# STM32WBA54 register map
File version: 1.0
CPU: CM33 r0p1, little endian, MPU, FPU, 4 interrupt priority bits
Registers are 32-bit, read-write, reset 0x0 unless marked. A register's access mark holds for its fields unless they carry their own. Offsets are from the block's base; [hi:lo] are bit positions; {n}, {i} and the like mark numbered series.

## EXTI — External interrupt/event controller
Base 0x46022000
Same registers: SEC_EXTI 0x56022000
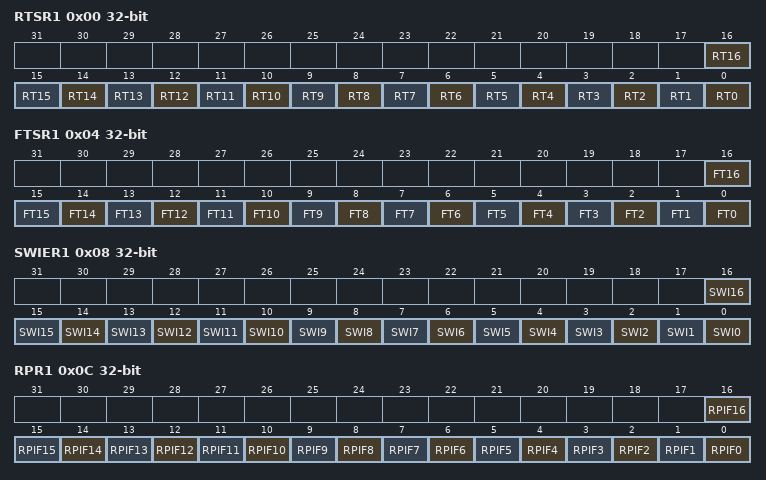
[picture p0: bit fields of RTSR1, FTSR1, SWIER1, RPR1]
0x00 RTSR1 — EXTI rising trigger selection register
  [n] RT{n} (n=0..16) — Rising trigger event configuration bit of configurable event input x When EXTI_SECCFGR.SECx is disabled, RTx can be accessed with non-secure and secure access. When EXTI_SECCFGR.SECx is enabled, RTx can only be accessed with secure access. Non-secure write to this bit x is discarded and non-secure read returns 0. When EXTI_PRIVCFGR.PRIVx is disabled, RTx can be accessed with unprivileged and privileged access. When EXTI_PRIVCFGR.PRIVx is enabled, RTx can only be accessed with privileged access. Unprivileged write to this bit x is discarded, unprivileged read returns 0.
0x04 FTSR1 — EXTI falling trigger selection register
  [n] FT{n} (n=0..16) — Falling trigger event configuration bit of configurable event input x When EXTI_SECCFGR.SECx is disabled, FTx can be accessed with non-secure and secure access. When EXTI_SECCFGR.SECx is enabled, FTx can only be accessed with secure access. Non-secure write to this FTx is discarded, non-secure read returns 0. When EXTI_PRIVCFGR.PRIVx is disabled, FTx can be accessed with unprivileged and privileged access. When EXTI_PRIVCFGR.PRIVx is enabled, FTx can only be accessed with privileged access. Unprivileged write to this FTx is discarded, unprivileged read returns 0.
0x08 SWIER1 — EXTI software interrupt event register
  [n] SWI{n} (n=0..16) — Software interrupt on event x When EXTI_SECFGR.SECx is disabled, SWIx can be accessed with non-secure and secure access. When EXTI_SECCFGR.SECx is enabled, SWIx can only be accessed with secure access. Non-secure write to this SWI x is discarded, non-secure read returns 0. When EXTI_PRIVCFGR.PRIVx is disabled, SWIx can be accessed with unprivileged and privileged access. When EXTI_PRIVCFGR.PRIVx is enabled, SWIx can only be accessed with privileged access. Unprivileged write to this SWIx is discarded, unprivileged read returns 0. A software interrupt is generated independently from the setting in EXTI_RTSR and EXTI_FTSR. It always returns 0 when read.
0x0C RPR1 — EXTI rising edge pending register
  [n] RPIF{n} (n=0..16) — configurable event inputs x rising edge pending bit When EXTI_SECCFGR.SECx is disabled, RPIFx can be accessed with non-secure and secure access. When EXTI_SECCFGR.SECx is enabled, RPIFx can only be accessed with secure access. Non-secure write to this RPIFx is discarded, non-secure read returns 0. When EXTI_PRIVCFGR.PRIVx is disabled, RPIFx can be accessed with unprivileged and privileged access. When EXTI_PRIVCFGR.PRIVx is enabled, RPIFx can only be accessed with privileged access. Unprivileged write to this RPIFx is discarded, unprivileged read returns 0. This bit is set when the rising edge event or an EXTI_SWIER software trigger arrives on the configurable event line. This bit is cleared by writing 1 to it.
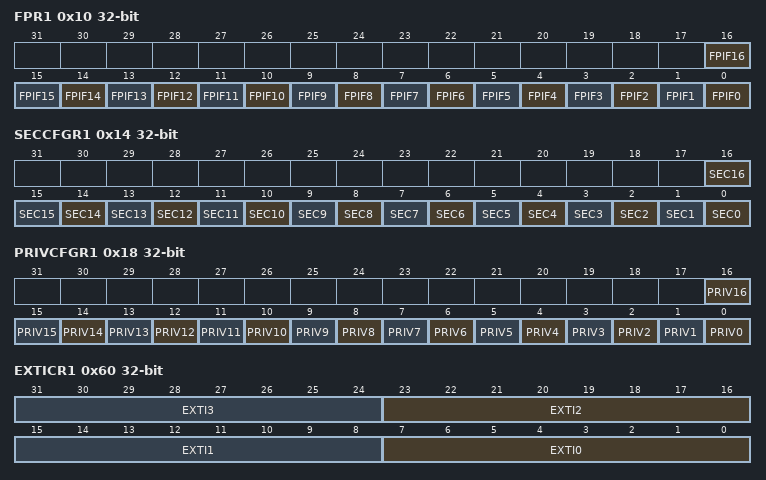
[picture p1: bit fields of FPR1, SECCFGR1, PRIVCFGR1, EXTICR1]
0x10 FPR1 — EXTI falling edge pending register
  [n] FPIF{n} (n=0..16) — configurable event inputs x falling edge pending bit When EXTI_SECCFGR.SECx is disabled, FPIFx can be accessed with non-secure and secure access. When EXTI_SECCFGR.SECx is enabled, FPIFx can only be accessed with secure access. Non-secure write to this FPIFx is discarded, non-secure read returns 0. When EXTI_PRIVCFGR.PRIVx is disabled, FPIFx can be accessed with unprivileged and privileged access. When EXTI_PRIVCFGR.PRIVx is enabled, FPIFx can only be accessed with privileged access. Unprivileged write to this FPIFx is discarded, unprivileged read returns 0. This bit is set when the falling edge event arrives on the configurable event line. This bit is cleared by writing 1 to it.
0x14 SECCFGR1 — EXTI security configuration register
  [n] SEC{n} (n=0..16) — Security enable on event input x When EXTI_PRIVCFGR.PRIVx is disabled, SECx can be accessed with privileged and unprivileged access. When EXTI_PRIVCFGR.PRIVx is enabled, SECx can only be written with privileged access. Unprivileged write to this SECx is discarded.
0x18 PRIVCFGR1 — EXTI privilege configuration register
  [n] PRIV{n} (n=0..16) — Security enable on event input x When EXTI_SECCFGR.SECx is disabled, PRIVx can be accessed with secure and non-secure access. When EXTI_SECCFGR.SECx is enabled, PRIVx can only be written with secure access. Non-secure write to this PRIVx is discarded.
0x60 EXTICR1 — EXTI external interrupt selection register
  [8n+7:8n] EXTI{n} (n=0..3) — EXTI{n} GPIO port selection These bits are written by software to select the source input for EXTI{n} external interrupt. When EXTI_SECCFGR.SEC{n} is disabled, EXTI{n} can be accessed with non-secure and secure access. When EXTI_SECCFGR.SEC{n} is enabled, EXTI{n} can only be accessed with secure access. Non-secure write is discarded and non-secure read returns 0. When EXTI_PRIVCFGR.PRIV{n} is disabled, EXTI{n} can be accessed with privileged and unprivileged access. When EXTI_PRIVCFGR.PRIV{n} is enabled, EXTI{n} can only be accessed with privileged access. Unprivileged write to this bit is discarded. Others: reserved
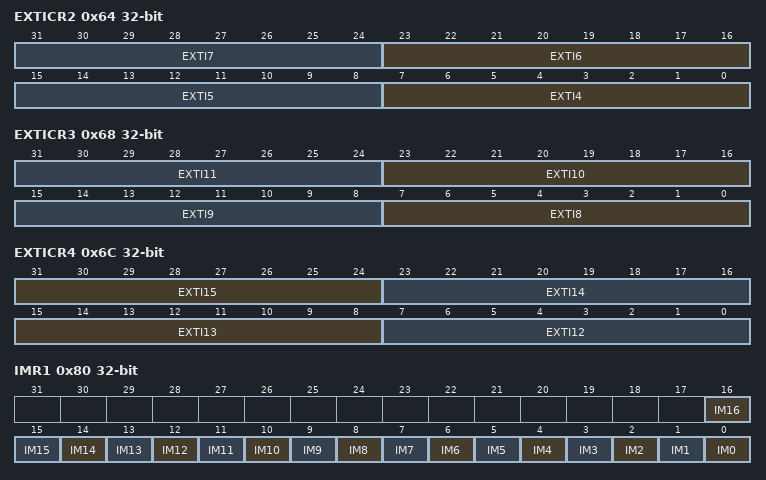
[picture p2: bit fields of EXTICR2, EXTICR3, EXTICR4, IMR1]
0x64 EXTICR2 — EXTI external interrupt selection register
  [8n-25:8n-32] EXTI{n} (n=4..7) — EXTI{n} GPIO port selection These bits are written by software to select the source input for EXTI{n} external interrupt. When EXTI_SECCFGR.SEC{n} is disabled, EXTI{n} can be accessed with non-secure and secure access. When EXTI_SECCFGR.SEC{n} is enabled, EXTI{n} can only be accessed with secure access. Non-secure write is discarded and non-secure read returns 0. When EXTI_PRIVCFGR.PRIV{n} is disabled, EXTI{n} can be accessed with privileged and unprivileged access. When EXTI_PRIVCFGR.PRIV{n} is enabled, EXTI{n} can only be accessed with privileged access. Unprivileged write to this bit is discarded. Others: reserved
0x68 EXTICR3 — EXTI external interrupt selection register
  [8n-57:8n-64] EXTI{n} (n=8..11) — EXTI{n} GPIO port selection These bits are written by software to select the source input for EXTI{n} external interrupt. When EXTI_SECCFGR.SEC{n} is disabled, EXTI{n} can be accessed with non-secure and secure access. When EXTI_SECCFGR.SEC{n} is enabled, EXTI{n} can only be accessed with secure access. Non-secure write is discarded and non-secure read returns 0. When EXTI_PRIVCFGR.PRIV{n} is disabled, EXTI{n} can be accessed with privileged and unprivileged access. When EXTI_PRIVCFGR.PRIV{n} is enabled, EXTI{n} can only be accessed with privileged access. Unprivileged write to this bit is discarded. Others: reserved
0x6C EXTICR4 — EXTI external interrupt selection register
  [31:24] EXTI15 — EXTI15 GPIO port selection These bits are written by software to select the source input for EXTI15 external interrupt. When EXTI_SECCFGR.SEC15 is disabled, EXTI15 can be accessed with non-secure and secure access. When EXTI_SECCFGR.SEC15 is enabled, EXTI15 can only be accessed with secure access. Non-secure write is discarded and non-secure read returns 0. When EXTI_PRIVCFGR.PRIV15 is disabled, EXTI15 can be accessed with privileged and unprivileged access. When EXTI_PRIVCFGR.PRIV15 is enabled, EXTI15 can only be accessed with privileged access. Unprivileged write to this bit is discarded. Others: reserved
  [23:16] EXTI14 — EXTI14 GPIO port selection These bits are written by software to select the source input for EXTI14 external interrupt. When EXTI_SECCFGR.SEC14 is disabled, EXTI14 can be accessed with non-secure and secure access. When EXTI_SECCFGR.SEC14 is enabled, EXTI14 can only be accessed with secure access. Non-secure write is discarded and non-secure read returns 0. When EXTI_PRIVCFGR.PRIV14 is disabled, EXTI14 can be accessed with privileged and unprivileged access. When EXTI_PRIVCFGR.PRIV14 is enabled, EXTI14 can only be accessed with privileged access. Unprivileged write to this bit is discarded. Others: reserved
  [15:8] EXTI13 — EXTI13 GPIO port selection These bits are written by software to select the source input for EXTI13 external interrupt. When EXTI_SECCFGR.SEC13 is disabled, EXTI13 can be accessed with non-secure and secure access. When EXTI_SECCFGR.SEC13 is enabled, EXTI13 can only be accessed with secure access. Non-secure write is discarded and non-secure read returns 0. When EXTI_PRIVCFGR.PRIV13 is disabled, EXTI13 can be accessed with privileged and unprivileged access. When EXTI_PRIVCFGR.PRIV13 is enabled, EXTI13 can only be accessed with privileged access. Unprivileged write to this bit is discarded. Others: reserved
  [7:0] EXTI12 — EXTI0 GPIO port selection These bits are written by software to select the source input for EXTI12 external interrupt. When EXTI_SECCFGR.SEC12 is disabled, EXTI12 can be accessed with non-secure and secure access. When EXTI_SECCFGR.SEC12 is enabled, EXTI12 can only be accessed with secure access. Non-secure write is discarded and non-secure read returns 0. When EXTI_PRIVCFGR.PRIV12 is disabled, EXTI12 can be accessed with privileged and unprivileged access. When EXTI_PRIVCFGR.PRIV12 is enabled, EXTI12 can only be accessed with privileged access. Unprivileged write to this bit is discarded. Others: reserved
0x70 LOCKR — EXTI lock register
  [0] LOCK — Global security and privilege configuration registers (EXTI_SECCFGR and EXTI_PRIVCFGR) lock This bit is written once after reset.
0x80 IMR1 — EXTI CPU wakeup with interrupt mask register
  [n] IM{n} (n=0..16) — CPU wakeup with interrupt mask on event input x When EXTI_SECCFGR.SECx is disabled, IMx can be accessed with non-secure and secure access. When EXTI_SECCFGR.SECx is enabled, IMx can only be accessed with secure access. Non-secure write to this bit is discarded and non-secure read returns 0. When EXTI_PRIVCFGR.PRIVx is disabled, IMx can be accessed with privileged and unprivileged access. When EXTI_PRIVCFGR.PRIVx is enabled, IMx can only be accessed with privileged access. Unprivileged write to this bit is discarded.
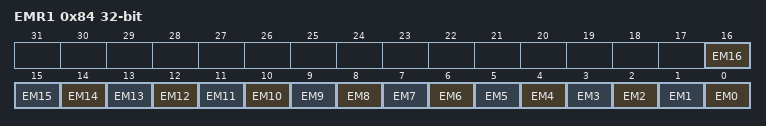
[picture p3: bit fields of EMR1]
0x84 EMR1 — EXTI CPU wakeup with event mask register
  [n] EM{n} (n=0..16) — CPU wakeup with event generation mask on event input x When EXTI_SECCFGR.SECx is disabled, EMx can be accessed with non-secure and secure access. When EXTI_SECCFGR.SECx is enabled, EMx can only be accessed with secure access. Non-secure write to this bit x is discarded and non-secure read returns 0. When EXTI_PRIVCFGR.PRIVx is disabled, EMx can be accessed with privileged and unprivileged access. When EXTI_PRIVCFGR.PRIVx is enabled, EMx can only be accessed with privileged access. Unprivileged write to this bit is discarded.
